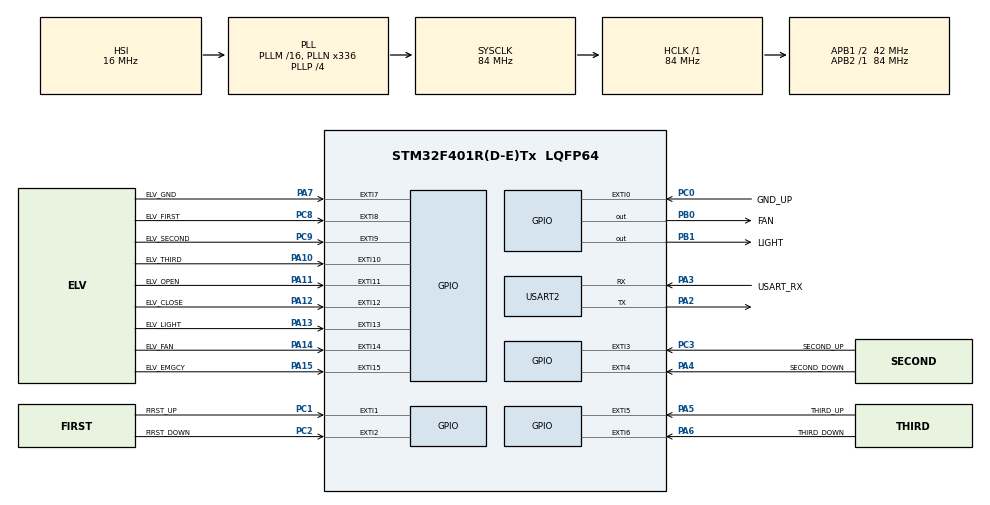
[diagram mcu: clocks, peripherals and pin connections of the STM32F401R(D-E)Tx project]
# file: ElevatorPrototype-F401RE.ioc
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Mcu.Family=STM32F4
Mcu.Name=STM32F401R(D-E)Tx
Mcu.Package=LQFP64
NVIC.EXTI0_IRQn=true\:0\:0\:false\:false\:true\:true\:true\:true
NVIC.EXTI15_10_IRQn=true\:0\:0\:false\:false\:true\:true\:true\:true
NVIC.EXTI1_IRQn=true\:0\:0\:false\:false\:true\:true\:true\:true
NVIC.EXTI2_IRQn=true\:0\:0\:false\:false\:true\:true\:true\:true
NVIC.EXTI3_IRQn=true\:0\:0\:false\:false\:true\:true\:true\:true
NVIC.EXTI4_IRQn=true\:0\:0\:false\:false\:true\:true\:true\:true
NVIC.EXTI9_5_IRQn=true\:0\:0\:false\:false\:true\:true\:true\:true
NVIC.PriorityGroup=NVIC_PRIORITYGROUP_0
PA10.GPIO_Label=ELV_THIRD
PA10.GPIO_ModeDefaultEXTI=GPIO_MODE_IT_FALLING
PA10.GPIO_PuPd=GPIO_PULLUP
PA10.Signal=GPXTI10
PA11.GPIO_Label=ELV_OPEN
PA11.GPIO_ModeDefaultEXTI=GPIO_MODE_IT_FALLING
PA11.GPIO_PuPd=GPIO_PULLUP
PA11.Signal=GPXTI11
PA12.GPIO_Label=ELV_CLOSE
PA12.GPIO_ModeDefaultEXTI=GPIO_MODE_IT_FALLING
PA12.GPIO_PuPd=GPIO_PULLUP
PA12.Signal=GPXTI12
PA13.GPIO_Label=ELV_LIGHT
PA13.GPIO_ModeDefaultEXTI=GPIO_MODE_IT_FALLING
PA13.GPIO_PuPd=GPIO_PULLUP
PA13.Signal=GPXTI13
PA14.GPIO_Label=ELV_FAN
PA14.GPIO_ModeDefaultEXTI=GPIO_MODE_IT_FALLING
PA14.GPIO_PuPd=GPIO_PULLUP
PA14.Signal=GPXTI14
PA15.GPIO_Label=ELV_EMGCY
PA15.GPIO_ModeDefaultEXTI=GPIO_MODE_IT_FALLING
PA15.GPIO_PuPd=GPIO_PULLUP
PA15.Signal=GPXTI15
PA2.Mode=Asynchronous
PA2.Signal=USART2_TX
PA3.GPIO_Label=USART_RX
PA3.GPIO_Mode=GPIO_MODE_AF_PP
PA3.GPIO_PuPd=GPIO_NOPULL
PA3.GPIO_Speed=GPIO_SPEED_FREQ_LOW
PA3.Mode=Asynchronous
PA3.Signal=USART2_RX
PA4.GPIO_Label=SECOND_DOWN
PA4.GPIO_ModeDefaultEXTI=GPIO_MODE_IT_FALLING
PA4.GPIO_PuPd=GPIO_PULLUP
PA4.Signal=GPXTI4
PA5.GPIO_Label=THIRD_UP
PA5.GPIO_ModeDefaultEXTI=GPIO_MODE_IT_FALLING
PA5.GPIO_PuPd=GPIO_PULLUP
PA5.Signal=GPXTI5
PA6.GPIO_Label=THIRD_DOWN
PA6.GPIO_ModeDefaultEXTI=GPIO_MODE_IT_FALLING
PA6.GPIO_PuPd=GPIO_PULLUP
PA6.Signal=GPXTI6
PA7.GPIO_Label=ELV_GND
PA7.GPIO_ModeDefaultEXTI=GPIO_MODE_IT_FALLING
PA7.GPIO_PuPd=GPIO_PULLUP
PA7.Signal=GPXTI7
PB0.GPIO_Label=FAN
PB0.Signal=GPIO_Output
PB1.GPIO_Label=LIGHT
PB1.Signal=GPIO_Output
PC0.GPIO_Label=GND_UP
PC0.GPIO_ModeDefaultEXTI=GPIO_MODE_IT_FALLING
PC0.GPIO_PuPd=GPIO_PULLUP
PC0.Signal=GPXTI0
PC1.GPIO_Label=FIRST_UP
PC1.GPIO_ModeDefaultEXTI=GPIO_MODE_IT_FALLING
PC1.GPIO_PuPd=GPIO_PULLUP
PC1.Signal=GPXTI1
PC2.GPIO_Label=FIRST_DOWN
PC2.GPIO_ModeDefaultEXTI=GPIO_MODE_IT_FALLING
PC2.GPIO_PuPd=GPIO_PULLUP
PC2.Signal=GPXTI2
PC3.GPIO_Label=SECOND_UP
PC3.GPIO_ModeDefaultEXTI=GPIO_MODE_IT_FALLING
PC3.GPIO_PuPd=GPIO_PULLUP
PC3.Signal=GPXTI3
PC8.GPIO_Label=ELV_FIRST
PC8.GPIO_ModeDefaultEXTI=GPIO_MODE_IT_FALLING
PC8.GPIO_PuPd=GPIO_PULLUP
PC8.Signal=GPXTI8
PC9.GPIO_Label=ELV_SECOND
PC9.GPIO_ModeDefaultEXTI=GPIO_MODE_IT_FALLING
PC9.GPIO_PuPd=GPIO_PULLUP
PC9.Signal=GPXTI9
ProjectManager.HeapSize=0x200
ProjectManager.StackSize=0x400
ProjectManager.TargetToolchain=STM32CubeIDE
RCC.AHBFreq_Value=84000000
RCC.APB1CLKDivider=RCC_HCLK_DIV2
RCC.APB1Freq_Value=42000000
RCC.APB1TimFreq_Value=84000000
RCC.APB2Freq_Value=84000000
RCC.APB2TimFreq_Value=84000000
RCC.CortexFreq_Value=84000000
RCC.HCLKFreq_Value=84000000
RCC.HSE_VALUE=8000000
RCC.HSI_VALUE=16000000
RCC.LSE_VALUE=32768
RCC.PLLN=336
RCC.PLLP=RCC_PLLP_DIV4
RCC.PLLQ=7
RCC.SYSCLKFreq_VALUE=84000000
RCC.SYSCLKSource=RCC_SYSCLKSOURCE_PLLCLK
RCC.VCOOutputFreq_Value=336000000
USART2.VirtualMode=VM_ASYNC
board=NUCLEO-F401RE

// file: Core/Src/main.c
/* USER CODE BEGIN Header */
/**
  ******************************************************************************
  * @file           : main.c
  * @brief          : Main program body
  ******************************************************************************
  * @attention
  *
  * Copyright (c) 2023 STMicroelectronics.
  * All rights reserved.
  *
  * This software is licensed under terms that can be found in the LICENSE file
  * in the root directory of this software component.
  * If no LICENSE file comes with this software, it is provided AS-IS.
  *
  ******************************************************************************
  */
/* USER CODE END Header */
#include "main.h"

UART_HandleTypeDef huart2;

void SystemClock_Config(void);
static void MX_GPIO_Init(void);
static void MX_USART2_UART_Init(void);

int main(void)
{

  /* MCU Configuration--------------------------------------------------------*/

  /* Reset of all peripherals, Initializes the Flash interface and the Systick. */
  HAL_Init();

  /* Configure the system clock */
  SystemClock_Config();

  /* Initialize all configured peripherals */
  MX_GPIO_Init();
  MX_USART2_UART_Init();

  /* Infinite loop */
  while (1)
  {

  }
}

void SystemClock_Config(void)
{
  RCC_OscInitTypeDef RCC_OscInitStruct = {0};
  RCC_ClkInitTypeDef RCC_ClkInitStruct = {0};

  /** Configure the main internal regulator output voltage
  */
  __HAL_RCC_PWR_CLK_ENABLE();
  __HAL_PWR_VOLTAGESCALING_CONFIG(PWR_REGULATOR_VOLTAGE_SCALE2);

  /** Initializes the RCC Oscillators according to the specified parameters
  * in the RCC_OscInitTypeDef structure.
  */
  RCC_OscInitStruct.OscillatorType = RCC_OSCILLATORTYPE_HSI;
  RCC_OscInitStruct.HSIState = RCC_HSI_ON;
  RCC_OscInitStruct.HSICalibrationValue = RCC_HSICALIBRATION_DEFAULT;
  RCC_OscInitStruct.PLL.PLLState = RCC_PLL_ON;
  RCC_OscInitStruct.PLL.PLLSource = RCC_PLLSOURCE_HSI;
  RCC_OscInitStruct.PLL.PLLM = 16;
  RCC_OscInitStruct.PLL.PLLN = 336;
  RCC_OscInitStruct.PLL.PLLP = RCC_PLLP_DIV4;
  RCC_OscInitStruct.PLL.PLLQ = 7;
  if (HAL_RCC_OscConfig(&RCC_OscInitStruct) != HAL_OK)
  {
    Error_Handler();
  }

  /** Initializes the CPU, AHB and APB buses clocks
  */
  RCC_ClkInitStruct.ClockType = RCC_CLOCKTYPE_HCLK|RCC_CLOCKTYPE_SYSCLK
                              |RCC_CLOCKTYPE_PCLK1|RCC_CLOCKTYPE_PCLK2;
  RCC_ClkInitStruct.SYSCLKSource = RCC_SYSCLKSOURCE_PLLCLK;
  RCC_ClkInitStruct.AHBCLKDivider = RCC_SYSCLK_DIV1;
  RCC_ClkInitStruct.APB1CLKDivider = RCC_HCLK_DIV2;
  RCC_ClkInitStruct.APB2CLKDivider = RCC_HCLK_DIV1;

  if (HAL_RCC_ClockConfig(&RCC_ClkInitStruct, FLASH_LATENCY_2) != HAL_OK)
  {
    Error_Handler();
  }
}

static void MX_USART2_UART_Init(void)
{

  huart2.Instance = USART2;
  huart2.Init.BaudRate = 115200;
  huart2.Init.WordLength = UART_WORDLENGTH_8B;
  huart2.Init.StopBits = UART_STOPBITS_1;
  huart2.Init.Parity = UART_PARITY_NONE;
  huart2.Init.Mode = UART_MODE_TX_RX;
  huart2.Init.HwFlowCtl = UART_HWCONTROL_NONE;
  huart2.Init.OverSampling = UART_OVERSAMPLING_16;
  if (HAL_UART_Init(&huart2) != HAL_OK)
  {
    Error_Handler();
  }

}

static void MX_GPIO_Init(void)
{
  GPIO_InitTypeDef GPIO_InitStruct = {0};

  /* GPIO Ports Clock Enable */
  __HAL_RCC_GPIOC_CLK_ENABLE();
  __HAL_RCC_GPIOA_CLK_ENABLE();
  __HAL_RCC_GPIOB_CLK_ENABLE();

  /*Configure GPIO pin Output Level */
  HAL_GPIO_WritePin(GPIOB, FAN_Pin|LIGHT_Pin, GPIO_PIN_RESET);

  /*Configure GPIO pins : GND_UP_Pin FIRST_UP_Pin FIRST_DOWN_Pin SECOND_UP_Pin
                           ELV_FIRST_Pin ELV_SECOND_Pin */
  GPIO_InitStruct.Pin = GND_UP_Pin|FIRST_UP_Pin|FIRST_DOWN_Pin|SECOND_UP_Pin
                          |ELV_FIRST_Pin|ELV_SECOND_Pin;
  GPIO_InitStruct.Mode = GPIO_MODE_IT_FALLING;
  GPIO_InitStruct.Pull = GPIO_PULLUP;
  HAL_GPIO_Init(GPIOC, &GPIO_InitStruct);

  /*Configure GPIO pins : SECOND_DOWN_Pin THIRD_UP_Pin THIRD_DOWN_Pin ELV_GND_Pin
                           ELV_THIRD_Pin ELV_OPEN_Pin ELV_CLOSE_Pin ELV_LIGHT_Pin
                           ELV_FAN_Pin ELV_EMGCY_Pin */
  GPIO_InitStruct.Pin = SECOND_DOWN_Pin|THIRD_UP_Pin|THIRD_DOWN_Pin|ELV_GND_Pin
                          |ELV_THIRD_Pin|ELV_OPEN_Pin|ELV_CLOSE_Pin|ELV_LIGHT_Pin
                          |ELV_FAN_Pin|ELV_EMGCY_Pin;
  GPIO_InitStruct.Mode = GPIO_MODE_IT_FALLING;
  GPIO_InitStruct.Pull = GPIO_PULLUP;
  HAL_GPIO_Init(GPIOA, &GPIO_InitStruct);

  /*Configure GPIO pins : FAN_Pin LIGHT_Pin */
  GPIO_InitStruct.Pin = FAN_Pin|LIGHT_Pin;
  GPIO_InitStruct.Mode = GPIO_MODE_OUTPUT_PP;
  GPIO_InitStruct.Pull = GPIO_NOPULL;
  GPIO_InitStruct.Speed = GPIO_SPEED_FREQ_LOW;
  HAL_GPIO_Init(GPIOB, &GPIO_InitStruct);

  /* EXTI interrupt init*/
  HAL_NVIC_SetPriority(EXTI0_IRQn, 0, 0);
  HAL_NVIC_EnableIRQ(EXTI0_IRQn);

  HAL_NVIC_SetPriority(EXTI1_IRQn, 0, 0);
  HAL_NVIC_EnableIRQ(EXTI1_IRQn);

  HAL_NVIC_SetPriority(EXTI2_IRQn, 0, 0);
  HAL_NVIC_EnableIRQ(EXTI2_IRQn);

  HAL_NVIC_SetPriority(EXTI3_IRQn, 0, 0);
  HAL_NVIC_EnableIRQ(EXTI3_IRQn);

  HAL_NVIC_SetPriority(EXTI4_IRQn, 0, 0);
  HAL_NVIC_EnableIRQ(EXTI4_IRQn);

  HAL_NVIC_SetPriority(EXTI9_5_IRQn, 0, 0);
  HAL_NVIC_EnableIRQ(EXTI9_5_IRQn);

  HAL_NVIC_SetPriority(EXTI15_10_IRQn, 0, 0);
  HAL_NVIC_EnableIRQ(EXTI15_10_IRQn);

}

/* USER CODE BEGIN 4 */
void HAL_GPIO_EXTI_Callback(uint16_t GPIO_Pin)
{
	switch (GPIO_Pin)
	{

	}
}
/* USER CODE END 4 */

void Error_Handler(void)
{
  __disable_irq();
  while (1)
  {
  }
}
